# f29h85x_gpio_ctrl_regs register map
Vendor: Texas Instruments
Peripheral module from a debugger description file (folder HSM).
Registers are 32-bit, read-write, no defined reset value unless marked. A register's access mark holds for its fields unless they carry their own. Offsets are as the file gives them; lines under a group give offsets from that group; [hi:lo] are bit positions; {n}, {i} and the like mark numbered series; 'fields as' and 'values as' point back to an identical list; <NAME> marks a mode.

## GPIO_CTRL_REGS — GPIO CTRL Registers
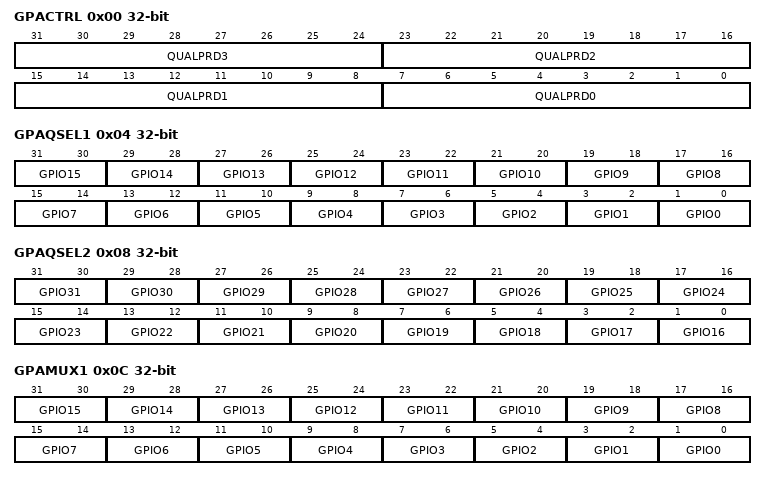
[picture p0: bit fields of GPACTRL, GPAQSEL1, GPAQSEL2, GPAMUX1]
0x00 GPACTRL — GPIO A Qualification Sampling Period Control (GPIO0 to 31)
  [8n+7:8n] QUALPRD{n} (n=0..3) — Qualification sampling period for GPIO{8n} to GPIO{8n+7}
0x04 GPAQSEL1 — GPIO A Qualifier Select 1 Register (GPIO0 to 15)
  [2n+1:2n] GPIO{n} (n=0..15) — Select input qualification type for GPIO{n}
0x08 GPAQSEL2 — GPIO A Qualifier Select 2 Register (GPIO16 to 31)
  [2n-31:2n-32] GPIO{n} (n=16..31) — Select input qualification type for GPIO{n}
0x0C GPAMUX1 — GPIO A Mux 1 Register (GPIO0 to 15)
  [2n+1:2n] GPIO{n} (n=0..15) — Defines pin-muxing selection for GPIO{n}
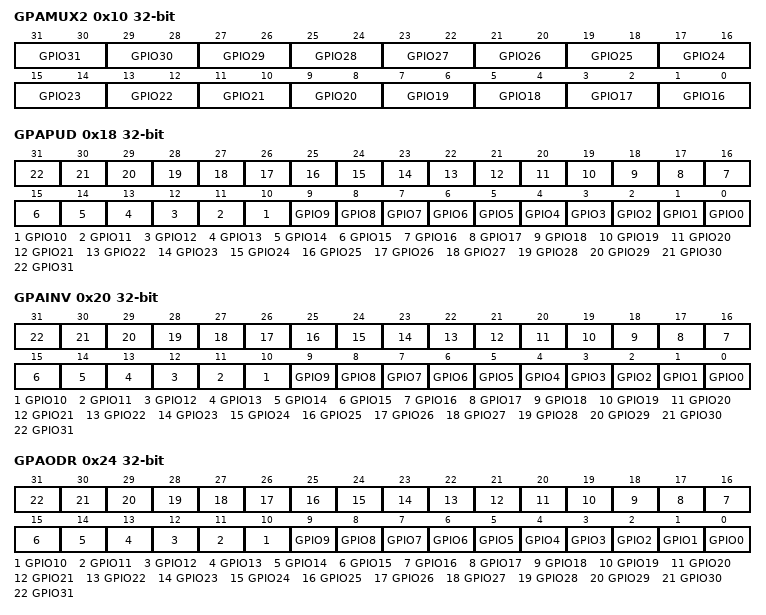
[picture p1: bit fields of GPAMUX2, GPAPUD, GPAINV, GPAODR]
0x10 GPAMUX2 — GPIO A Mux 2 Register (GPIO16 to 31)
  [2n-31:2n-32] GPIO{n} (n=16..31) — Defines pin-muxing selection for GPIO{n}
0x18 GPAPUD — GPIO A Pull Up Disable Register (GPIO0 to 31)
  [n] GPIO{n} (n=0..31) — Pull-Up Disable control for this pin
0x20 GPAINV — GPIO A Input Polarity Invert Registers (GPIO0 to 31)
  [n] GPIO{n} (n=0..31) — Input inversion control for this pin
0x24 GPAODR — GPIO A Open Drain Output Register (GPIO0 to GPIO31)
  [n] GPIO{n} (n=0..31) — Outpout Open-Drain control for this pin
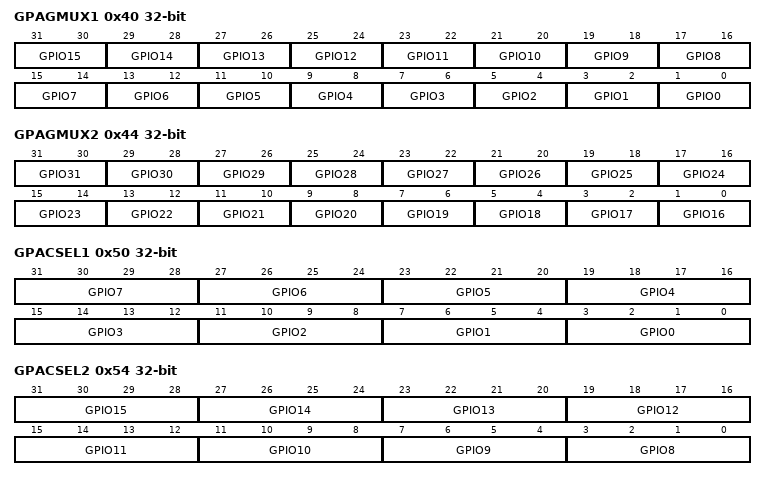
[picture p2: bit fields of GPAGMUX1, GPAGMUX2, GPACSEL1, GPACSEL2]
0x40 GPAGMUX1 — GPIO A Peripheral Group Mux (GPIO0 to 15)
  fields as GPAMUX1
0x44 GPAGMUX2 — GPIO A Peripheral Group Mux (GPIO16 to 31)
  fields as GPAMUX2
0x50 GPACSEL1 — GPIO A Core Select Register (GPIO0 to 7)
  [4n+3:4n] GPIO{n} (n=0..7) — GPIO{n} Controller CPU Select
0x54 GPACSEL2 — GPIO A Core Select Register (GPIO8 to 15)
  [4n-29:4n-32] GPIO{n} (n=8..15) — GPIO{n} Controller CPU Select
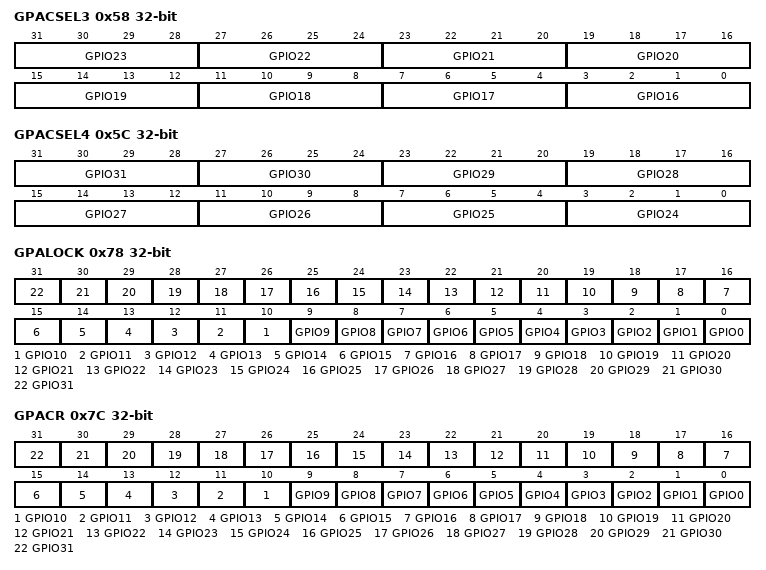
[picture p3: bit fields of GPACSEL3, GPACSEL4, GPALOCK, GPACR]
0x58 GPACSEL3 — GPIO A Core Select Register (GPIO16 to 23)
  [4n-61:4n-64] GPIO{n} (n=16..23) — GPIO{n} Controller CPU Select
0x5C GPACSEL4 — GPIO A Core Select Register (GPIO24 to 31)
  [4n-93:4n-96] GPIO{n} (n=24..31) — GPIO{n} Controller CPU Select
0x78 GPALOCK — GPIO A Lock Configuration Register (GPIO0 to 31)
  [n] GPIO{n} (n=0..31) — Configuration Lock bit for this pin
0x7C GPACR — GPIO A Lock Commit Register (GPIO0 to 31)
  [n] GPIO{n} (n=0..31) — Configuration lock commit bit for this pin
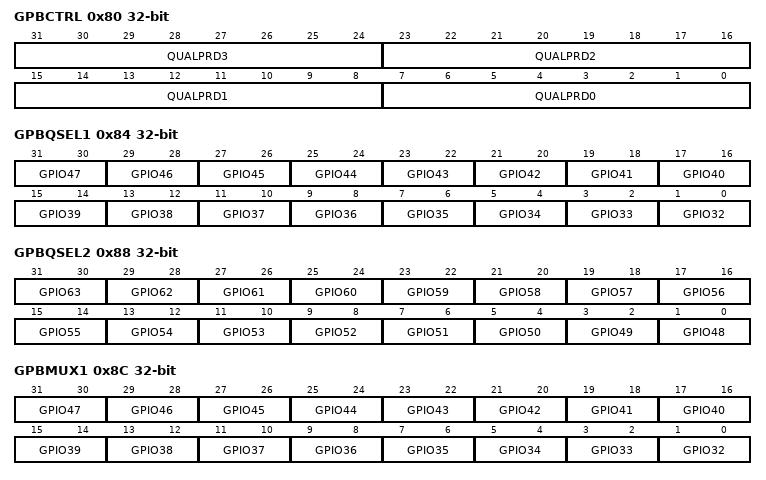
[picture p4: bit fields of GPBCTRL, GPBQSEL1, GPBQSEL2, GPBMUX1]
0x80 GPBCTRL — GPIO B Qualification Sampling Period Control (GPIO32 to 63)
  [8n+7:8n] QUALPRD{n} (n=0..3) — Qualification sampling period for GPIO{8n+32} to GPIO{8n+39}
0x84 GPBQSEL1 — GPIO B Qualifier Select 1 Register (GPIO32 to 47)
  [2n-63:2n-64] GPIO{n} (n=32..47) — Select input qualification type for GPIO{n}
0x88 GPBQSEL2 — GPIO B Qualifier Select 2 Register (GPIO48 to 63)
  [2n-95:2n-96] GPIO{n} (n=48..63) — Select input qualification type for GPIO{n}
0x8C GPBMUX1 — GPIO B Mux 1 Register (GPIO32 to 47)
  [2n-63:2n-64] GPIO{n} (n=32..47) — Defines pin-muxing selection for GPIO{n}
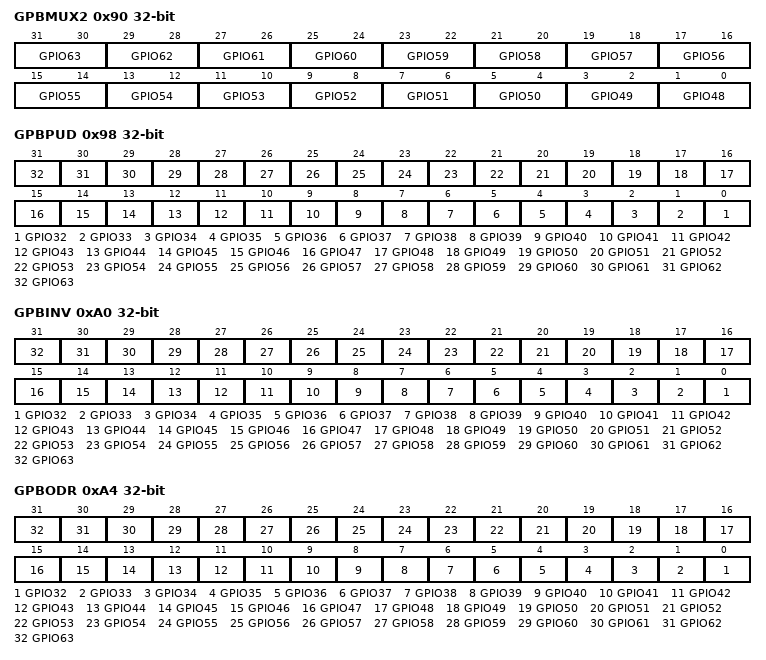
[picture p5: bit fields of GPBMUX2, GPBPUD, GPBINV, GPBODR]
0x90 GPBMUX2 — GPIO B Mux 2 Register (GPIO48 to 63)
  [2n-95:2n-96] GPIO{n} (n=48..63) — Defines pin-muxing selection for GPIO{n}
0x98 GPBPUD — GPIO B Pull Up Disable Register (GPIO32 to 63)
  [n-32] GPIO{n} (n=32..63) — Pull-Up Disable control for this pin
0xA0 GPBINV — GPIO B Input Polarity Invert Registers (GPIO32 to 63)
  [n-32] GPIO{n} (n=32..63) — Input inversion control for this pin
0xA4 GPBODR — GPIO B Open Drain Output Register (GPIO32 to GPIO63)
  [n-32] GPIO{n} (n=32..63) — Outpout Open-Drain control for this pin
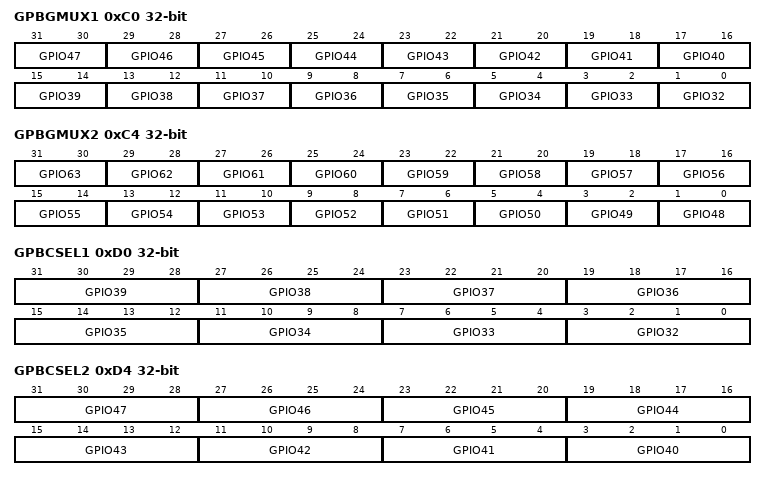
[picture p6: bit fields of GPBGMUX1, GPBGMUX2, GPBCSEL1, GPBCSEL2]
0xC0 GPBGMUX1 — GPIO B Peripheral Group Mux (GPIO32 to 47)
  fields as GPBMUX1
0xC4 GPBGMUX2 — GPIO B Peripheral Group Mux (GPIO48 to 63)
  fields as GPBMUX2
0xD0 GPBCSEL1 — GPIO B Core Select Register (GPIO32 to 39)
  [4n-125:4n-128] GPIO{n} (n=32..39) — GPIO{n} Controller CPU Select
0xD4 GPBCSEL2 — GPIO B Core Select Register (GPIO40 to 47)
  [4n-157:4n-160] GPIO{n} (n=40..47) — GPIO{n} Controller CPU Select
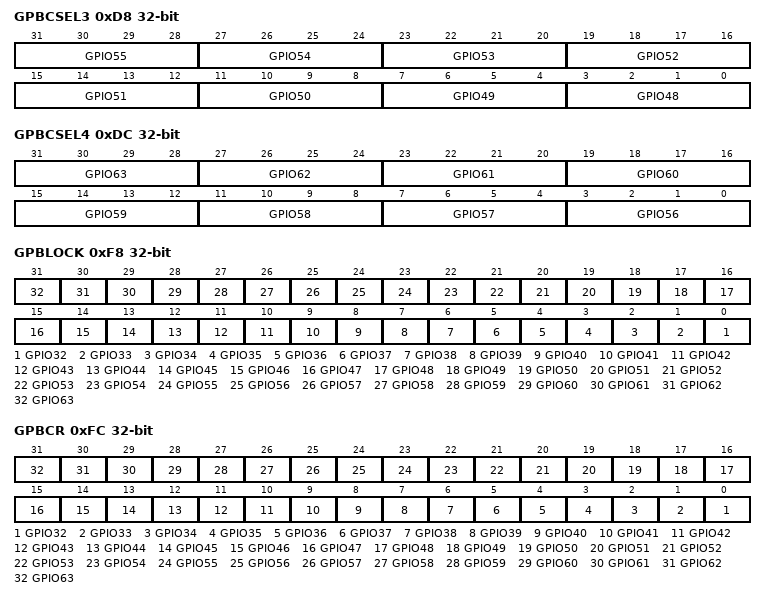
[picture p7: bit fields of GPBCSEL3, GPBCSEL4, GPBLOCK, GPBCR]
0xD8 GPBCSEL3 — GPIO B Core Select Register (GPIO48 to 55)
  [4n-189:4n-192] GPIO{n} (n=48..55) — GPIO{n} Controller CPU Select
0xDC GPBCSEL4 — GPIO B Core Select Register (GPIO56 to 63)
  [4n-221:4n-224] GPIO{n} (n=56..63) — GPIO{n} Controller CPU Select
0xF8 GPBLOCK — GPIO B Lock Configuration Register (GPIO32 to 63)
  [n-32] GPIO{n} (n=32..63) — Configuration Lock bit for this pin
0xFC GPBCR — GPIO B Lock Commit Register (GPIO32 to 63)
  [n-32] GPIO{n} (n=32..63) — Configuration lock commit bit for this pin
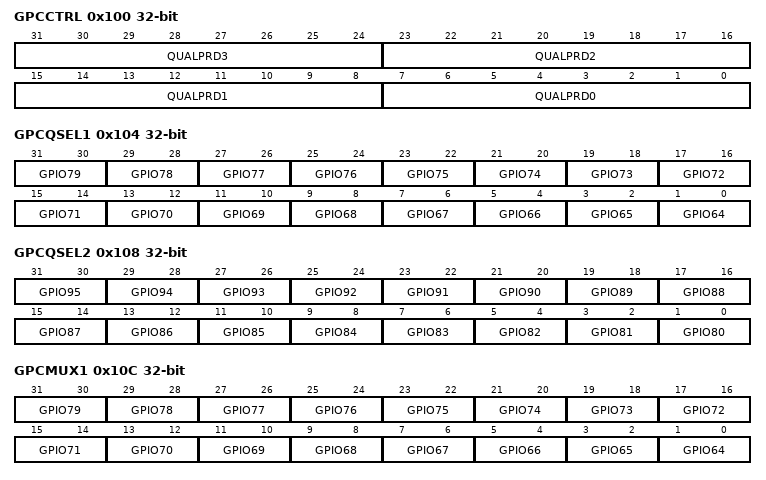
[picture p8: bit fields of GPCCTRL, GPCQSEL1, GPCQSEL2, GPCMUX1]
0x100 GPCCTRL — GPIO C Qualification Sampling Period Control (GPIO64 to 95)
  [8n+7:8n] QUALPRD{n} (n=0..3) — Qualification sampling period for GPIO{8n+64} to GPIO{8n+71}
0x104 GPCQSEL1 — GPIO C Qualifier Select 1 Register (GPIO64 to 79)
  [2n-127:2n-128] GPIO{n} (n=64..79) — Select input qualification type for GPIO{n}
0x108 GPCQSEL2 — GPIO C Qualifier Select 2 Register (GPIO80 to 95)
  [2n-159:2n-160] GPIO{n} (n=80..95) — Select input qualification type for GPIO{n}
0x10C GPCMUX1 — GPIO C Mux 1 Register (GPIO64 to 79)
  [2n-127:2n-128] GPIO{n} (n=64..79) — Defines pin-muxing selection for GPIO{n}
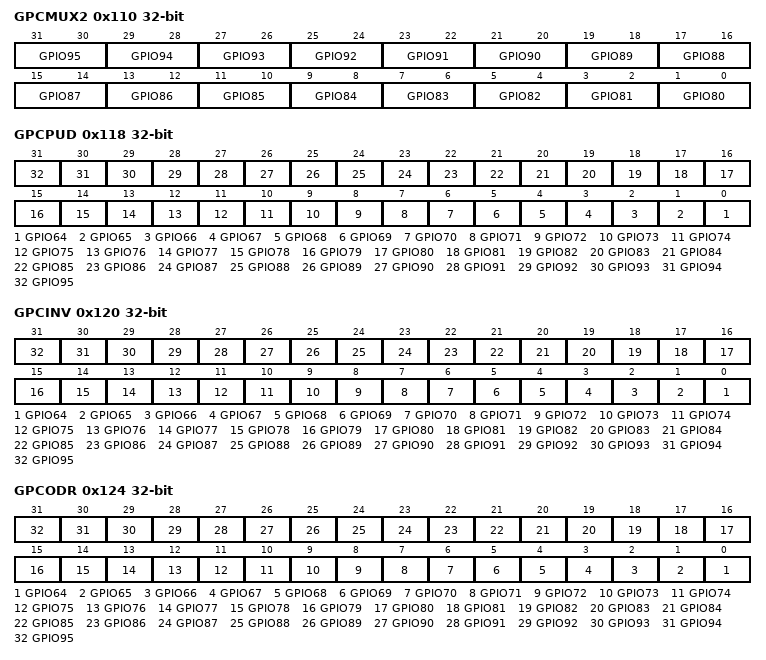
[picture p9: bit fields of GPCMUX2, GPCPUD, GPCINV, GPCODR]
0x110 GPCMUX2 — GPIO C Mux 2 Register (GPIO80 to 95)
  [2n-159:2n-160] GPIO{n} (n=80..95) — Defines pin-muxing selection for GPIO{n}
0x118 GPCPUD — GPIO C Pull Up Disable Register (GPIO64 to 95)
  [n-64] GPIO{n} (n=64..95) — Pull-Up Disable control for this pin
0x120 GPCINV — GPIO C Input Polarity Invert Registers (GPIO64 to 95)
  [n-64] GPIO{n} (n=64..95) — Input inversion control for this pin
0x124 GPCODR — GPIO C Open Drain Output Register (GPIO64 to GPIO95)
  [n-64] GPIO{n} (n=64..95) — Outpout Open-Drain control for this pin
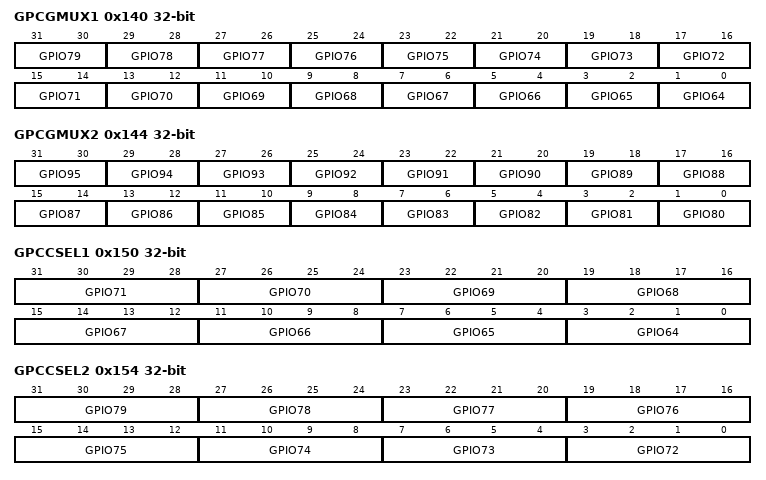
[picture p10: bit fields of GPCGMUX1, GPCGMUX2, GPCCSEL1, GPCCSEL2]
0x140 GPCGMUX1 — GPIO C Peripheral Group Mux (GPIO64 to 79)
  fields as GPCMUX1
0x144 GPCGMUX2 — GPIO C Peripheral Group Mux (GPIO80 to 95)
  fields as GPCMUX2
0x150 GPCCSEL1 — GPIO C Core Select Register (GPIO64 to 71)
  [4n-253:4n-256] GPIO{n} (n=64..71) — GPIO{n} Controller CPU Select
0x154 GPCCSEL2 — GPIO C Core Select Register (GPIO72 to 79)
  [4n-285:4n-288] GPIO{n} (n=72..79) — GPIO{n} Controller CPU Select
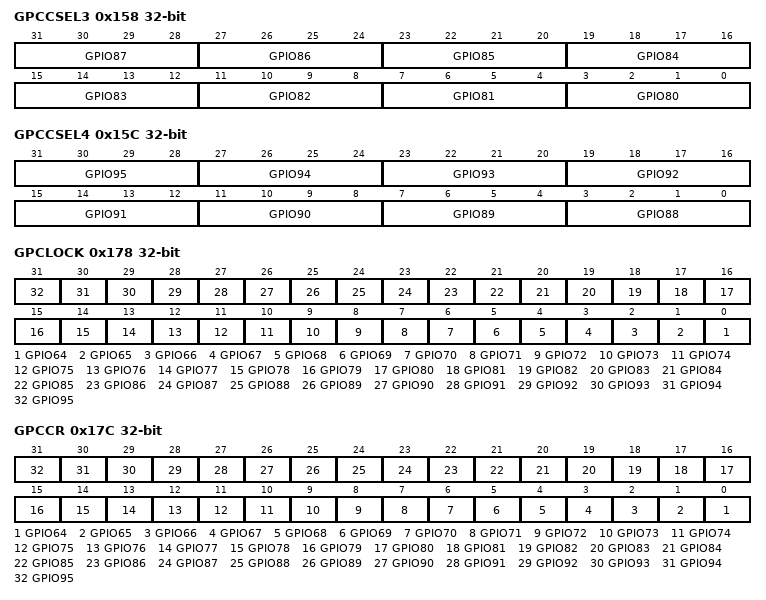
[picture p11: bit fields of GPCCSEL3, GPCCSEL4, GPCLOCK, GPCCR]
0x158 GPCCSEL3 — GPIO C Core Select Register (GPIO80 to 87)
  [4n-317:4n-320] GPIO{n} (n=80..87) — GPIO{n} Controller CPU Select
0x15C GPCCSEL4 — GPIO C Core Select Register (GPIO88 to 95)
  [4n-349:4n-352] GPIO{n} (n=88..95) — GPIO{n} Controller CPU Select
0x178 GPCLOCK — GPIO C Lock Configuration Register (GPIO64 to 95)
  [n-64] GPIO{n} (n=64..95) — Configuration Lock bit for this pin
0x17C GPCCR — GPIO C Lock Commit Register (GPIO64 to 95)
  [n-64] GPIO{n} (n=64..95) — Configuration lock commit bit for this pin
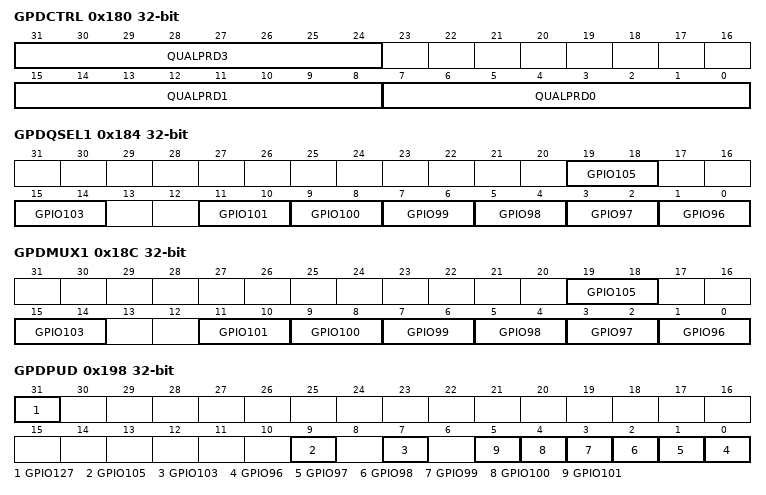
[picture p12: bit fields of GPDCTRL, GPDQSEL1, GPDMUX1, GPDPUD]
0x180 GPDCTRL — GPIO D Qualification Sampling Period Control (GPIO96 to 127)
  [31:24] QUALPRD3 — Qualification sampling period for GPIO120 to GPIO127
  [15:8] QUALPRD1 — Qualification sampling period for GPIO104 to GPIO111
  [7:0] QUALPRD0 — Qualification sampling period for GPIO96 to GPIO103
0x184 GPDQSEL1 — GPIO D Qualifier Select 1 Register (GPIO96 to 111)
  [19:18] GPIO105 — Select input qualification type for GPIO105
  [15:14] GPIO103 — Select input qualification type for GPIO103
  [2n-191:2n-192] GPIO{n} (n=96..101) — Select input qualification type for GPIO{n}
0x188 GPDQSEL2 — GPIO D Qualifier Select 2 Register (GPIO112 to 127)
  [31:30] GPIO127 — Select input qualification type for GPIO127
0x18C GPDMUX1 — GPIO D Mux 1 Register (GPIO96 to 111)
  [19:18] GPIO105 — Defines pin-muxing selection for GPIO105
  [15:14] GPIO103 — Defines pin-muxing selection for GPIO103
  [2n-191:2n-192] GPIO{n} (n=96..101) — Defines pin-muxing selection for GPIO{n}
0x190 GPDMUX2 — GPIO D Mux 2 Register (GPIO112 to 127)
  [31:30] GPIO127 — Defines pin-muxing selection for GPIO127
0x198 GPDPUD — GPIO D Pull Up Disable Register (GPIO96 to 127)
  [31] GPIO127 — Pull-Up Disable control for this pin
  [9] GPIO105 — Pull-Up Disable control for this pin
  [7] GPIO103 — Pull-Up Disable control for this pin
  [n-96] GPIO{n} (n=96..101) — Pull-Up Disable control for this pin
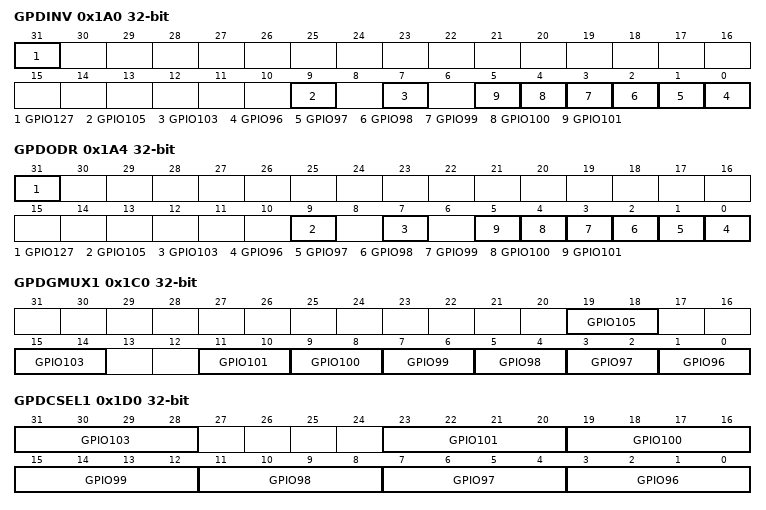
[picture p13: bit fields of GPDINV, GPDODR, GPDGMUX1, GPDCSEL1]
0x1A0 GPDINV — GPIO D Input Polarity Invert Registers (GPIO96 to 127)
  [31] GPIO127 — Input inversion control for this pin
  [9] GPIO105 — Input inversion control for this pin
  [7] GPIO103 — Input inversion control for this pin
  [n-96] GPIO{n} (n=96..101) — Input inversion control for this pin
0x1A4 GPDODR — GPIO D Open Drain Output Register (GPIO96 to GPIO127)
  [31] GPIO127 — Outpout Open-Drain control for this pin
  [9] GPIO105 — Outpout Open-Drain control for this pin
  [7] GPIO103 — Outpout Open-Drain control for this pin
  [n-96] GPIO{n} (n=96..101) — Outpout Open-Drain control for this pin
0x1C0 GPDGMUX1 — GPIO D Peripheral Group Mux (GPIO96 to 111)
  fields as GPDMUX1
0x1C4 GPDGMUX2 — GPIO D Peripheral Group Mux (GPIO112 to 127)
  [31:30] GPIO127 — Defines pin-muxing selection for GPIO127
0x1D0 GPDCSEL1 — GPIO D Core Select Register (GPIO96 to 103)
  [31:28] GPIO103 — GPIO103 Controller CPU Select
  [4n-381:4n-384] GPIO{n} (n=96..101) — GPIO{n} Controller CPU Select
0x1D4 GPDCSEL2 — GPIO D Core Select Register (GPIO104 to 111)
  [7:4] GPIO105 — GPIO105 Controller CPU Select
0x1D8 GPDCSEL3 access not given — GPIO D Core Select Register (GPIO112 to 119)
0x1DC GPDCSEL4 — GPIO D Core Select Register (GPIO120 to 127)
  [31:28] GPIO127 — GPIO127 Controller CPU Select
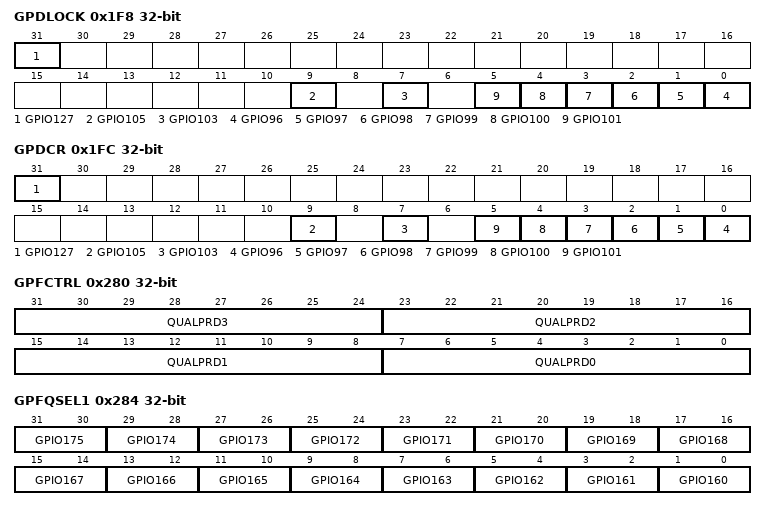
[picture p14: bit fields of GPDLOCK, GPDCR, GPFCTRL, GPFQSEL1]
0x1F8 GPDLOCK — GPIO D Lock Configuration Register (GPIO96 to 127)
  [31] GPIO127 — Configuration Lock bit for this pin
  [9] GPIO105 — Configuration Lock bit for this pin
  [7] GPIO103 — Configuration Lock bit for this pin
  [n-96] GPIO{n} (n=96..101) — Configuration Lock bit for this pin
0x1FC GPDCR — GPIO D Lock Commit Register (GPIO96 to 127)
  [31] GPIO127 — Configuration lock commit bit for this pin
  [9] GPIO105 — Configuration lock commit bit for this pin
  [7] GPIO103 — Configuration lock commit bit for this pin
  [n-96] GPIO{n} (n=96..101) — Configuration lock commit bit for this pin
0x280 GPFCTRL — GPIO F Qualification Sampling Period Control (GPIO160 to 191)
  [31:24] QUALPRD3 — Qualification sampling period for GPIO184 to GPIO191
  [23:16] QUALPRD2 — Qualification sampling period for GPIO176 to GPIO183
  [15:8] QUALPRD1 — Qualification sampling period for GPIO168
  [7:0] QUALPRD0 — Qualification sampling period for GPIO160 to GPIO167
0x284 GPFQSEL1 — GPIO F Qualifier Select 1 Register (GPIO160 to 168)
  [2n-319:2n-320] GPIO{n} (n=160..175) — Select input qualification type for GPIO{n}
0x288 GPFQSEL2 — GPIO F Qualifier Select 2 Register (GPIO176 to 191)
  [2n-351:2n-352] GPIO{n} (n=176..191) — Select input qualification type for GPIO{n}
0x28C GPFMUX1 — GPIO F Mux 1 Register (GPIO160 to 175)
  [2n-319:2n-320] GPIO{n} (n=160..175) — Defines pin-muxing selection for GPIO{n}
0x290 GPFMUX2 — GPIO F Mux 2 Register (GPIO176 to 191)
  [2n-351:2n-352] GPIO{n} (n=176..191) — Defines pin-muxing selection for GPIO{n}
0x298 GPFPUD — GPIO F Pull Up Disable Register (GPIO160 to 191)
  [n-160] GPIO{n} (n=160..191) — Pull-Up Disable control for this pin
0x2A0 GPFINV — GPIO F Input Polarity Invert Registers (GPIO160 to 191)
  [n-160] GPIO{n} (n=160..191) — Input inversion control for this pin
0x2A8 GPFAMSEL — GPIO F Analog Mode Select register (GPIO160 to GPIO191)
  [n-160] GPIO{n} (n=160..191) — Analog Mode select for this pin
0x2C0 GPFGMUX1 — GPIO F Peripheral Group Mux (GPIO160 to 175)
  fields as GPFMUX1
0x2C4 GPFGMUX2 — GPIO F Peripheral Group Mux (GPIO176 to 191)
  fields as GPFMUX2
0x2D0 GPFCSEL1 — GPIO F Core Select Register (GPIO160 to 167)
  [4n-637:4n-640] GPIO{n} (n=160..167) — GPIO{n} Controller CPU Select
0x2D4 GPFCSEL2 — GPIO F Core Select Register (GPIO168 to 175)
  [4n-669:4n-672] GPIO{n} (n=168..175) — GPIO{n} Controller CPU Select
0x2D8 GPFCSEL3 — GPIO F Core Select Register (GPIO176 to 183)
  [4n-701:4n-704] GPIO{n} (n=176..183) — GPIO{n} Controller CPU Select
0x2DC GPFCSEL4 — GPIO F Core Select Register (GPIO184 to 191)
  [4n-733:4n-736] GPIO{n} (n=184..191) — GPIO{n} Controller CPU Select
0x2F8 GPFLOCK — GPIO F Lock Configuration Register (GPIO160 to 191)
  [n-160] GPIO{n} (n=160..191) — Configuration Lock bit for this pin
0x2FC GPFCR — GPIO F Lock Commit Register (GPIO160 to 191)
  [n-160] GPIO{n} (n=160..191) — Configuration lock commit bit for this pin
0x300 GPGCTRL — GPIO G Qualification Sampling Period Control (GPIO192 to 223)
  [8n+7:8n] QUALPRD{n} (n=0..3) — Qualification sampling period for GPIO{8n+192} to GPIO{8n+199}
0x304 GPGQSEL1 — GPIO G Qualifier Select 1 Register (GPIO192 to 207)
  [2n-383:2n-384] GPIO{n} (n=192..207) — Select input qualification type for GPIO{n}
0x308 GPGQSEL2 — GPIO G Qualifier Select 2 Register (GPIO208 to 223)
  [2n-415:2n-416] GPIO{n} (n=219..223) — Select input qualification type for GPIO{n}
  [2n-415:2n-416] GPIO{n} (n=208..213) — Select input qualification type for GPIO{n}
0x30C GPGMUX1 — GPIO G Mux 1 Register (GPIO192 to 207)
  [2n-383:2n-384] GPIO{n} (n=192..207) — Defines pin-muxing selection for GPIO{n}
0x310 GPGMUX2 — GPIO G Mux 2 Register (GPIO208 to 223)
  [2n-415:2n-416] GPIO{n} (n=219..223) — Defines pin-muxing selection for GPIO{n}
  [2n-415:2n-416] GPIO{n} (n=208..213) — Defines pin-muxing selection for GPIO{n}
0x318 GPGPUD — GPIO G Pull Up Disable Register (GPIO192 to 223)
  [n-192] GPIO{n} (n=219..223) — Pull-Up Disable control for this pin
  [n-192] GPIO{n} (n=192..213) — Pull-Up Disable control for this pin
0x320 GPGINV — GPIO G Input Polarity Invert Registers (GPIO192 to 223)
  [n-192] GPIO{n} (n=219..223) — Input inversion control for this pin
  [n-192] GPIO{n} (n=192..213) — Input inversion control for this pin
0x324 GPGODR — GPIO G Open Drain Output Register (GPIO192 to 223)
  [n-192] GPIO{n} (n=219..223) — Outpout Open-Drain control for this pin
0x328 GPGAMSEL — GPIO G Analog Mode Select register (GPIO192 to 223)
  [n-192] GPIO{n} (n=192..213) — Analog Mode select for this pin
0x340 GPGGMUX1 — GPIO G Peripheral Group Mux (GPIO192 to 207)
  fields as GPGMUX1
0x344 GPGGMUX2 — GPIO G Peripheral Group Mux (GPIO208 to 223)
  fields as GPGMUX2
0x350 GPGCSEL1 — GPIO G Core Select Register (GPIO192 to 199)
  [4n-765:4n-768] GPIO{n} (n=192..199) — GPIO{n} Controller CPU Select
0x354 GPGCSEL2 — GPIO G Core Select Register (GPIO200 to 207)
  [4n-797:4n-800] GPIO{n} (n=200..207) — GPIO{n} Controller CPU Select
0x358 GPGCSEL3 — GPIO G Core Select Register (GPIO208 to 215)
  [4n-829:4n-832] GPIO{n} (n=208..213) — GPIO{n} Controller CPU Select
0x35C GPGCSEL4 — GPIO G Core Select Register (GPIO216 to 223)
  [4n-861:4n-864] GPIO{n} (n=219..223) — GPIO{n} Controller CPU Select
0x378 GPGLOCK — GPIO G Lock Configuration Register (GPIO192 to 223)
  [n-192] GPIO{n} (n=219..223) — Configuration Lock bit for this pin
  [n-192] GPIO{n} (n=192..213) — Configuration Lock bit for this pin
0x37C GPGCR — GPIO G Lock Commit Register (GPIO192 to 223)
  [n-192] GPIO{n} (n=219..223) — Configuration lock commit bit for this pin
  [n-192] GPIO{n} (n=192..213) — Configuration lock commit bit for this pin
0x380 GPHCTRL — GPIO H Qualification Sampling Period Control (GPIO224 to 255)
  [8n+7:8n] QUALPRD{n} (n=0..3) — Qualification sampling period for GPIO{8n+224} to GPIO{8n+231}
0x384 GPHQSEL1 — GPIO H Qualifier Select 1 Register (GPIO224 to 239)
  [2n-447:2n-448] GPIO{n} (n=224..239) — Select input qualification type for this GPIO Pin
0x388 GPHQSEL2 — GPIO H Qualifier Select 2 Register (GPIO240 to 255)
  [2n-479:2n-480] GPIO{n} (n=240..249) — Select input qualification type for this GPIO Pin
0x38C GPHMUX1 — GPIO H Mux 1 Register (GPIO224 to 239)
  [2n-447:2n-448] GPIO{n} (n=224..239) — Defines pin-muxing selection for GPIO{n}
0x390 GPHMUX2 — GPIO H Mux 2 Register (GPIO240 to 255)
  [2n-479:2n-480] GPIO{n} (n=240..249) — Defines pin-muxing selection for GPIO{n}
0x398 GPHPUD — GPIO H Pull Up Disable Register (GPIO224 to 255)
  [n-224] GPIO{n} (n=224..249) — Pull-Up Disable control for this pin
0x3A0 GPHINV — GPIO H Input Polarity Invert Registers (GPIO224 to 255)
  [n-224] GPIO{n} (n=224..249) — Input inversion control for this pin
0x3A4 GPHODR — GPIO H Open Drain Output Register (GPIO224 to GPIO255)
  [n-224] GPIO{n} (n=224..249) — Outpout Open-Drain control for this pin
0x3A8 GPHAMSEL — GPIO H Analog Mode Select register (GPIO224 to GPIO255)
  [n-224] GPIO{n} (n=224..249) — Analog Mode select for this pin
0x3C0 GPHGMUX1 — GPIO H Peripheral Group Mux (GPIO224 to 239)
  fields as GPHMUX1
0x3C4 GPHGMUX2 — GPIO H Peripheral Group Mux (GPIO240 to 255)
  fields as GPHMUX2
0x3D0 GPHCSEL1 — GPIO H Core Select Register (GPIO224 to 231)
  [4n-893:4n-896] GPIO{n} (n=224..231) — GPIO{n} Controller CPU Select
0x3D4 GPHCSEL2 — GPIO H Core Select Register (GPIO232 to 239)
  [4n-925:4n-928] GPIO{n} (n=232..239) — GPIO{n} Controller CPU Select
0x3D8 GPHCSEL3 — GPIO H Core Select Register (GPIO240 to 247)
  [4n-957:4n-960] GPIO{n} (n=240..247) — GPIO{n} Controller CPU Select
0x3DC GPHCSEL4 — GPIO H Core Select Register (GPIO248 to 255)
  [7:4] GPIO249 — GPIO249 Controller CPU Select
  [3:0] GPIO248 — GPIO248 Controller CPU Select
0x3F8 GPHLOCK — GPIO H Lock Configuration Register (GPIO224 to 255)
  [n-224] GPIO{n} (n=224..249) — Configuration Lock bit for this pin
0x3FC GPHCR — GPIO H Lock Commit Register (GPIO224 to 255)
  [n-224] GPIO{n} (n=224..249) — Configuration lock commit bit for this pin
